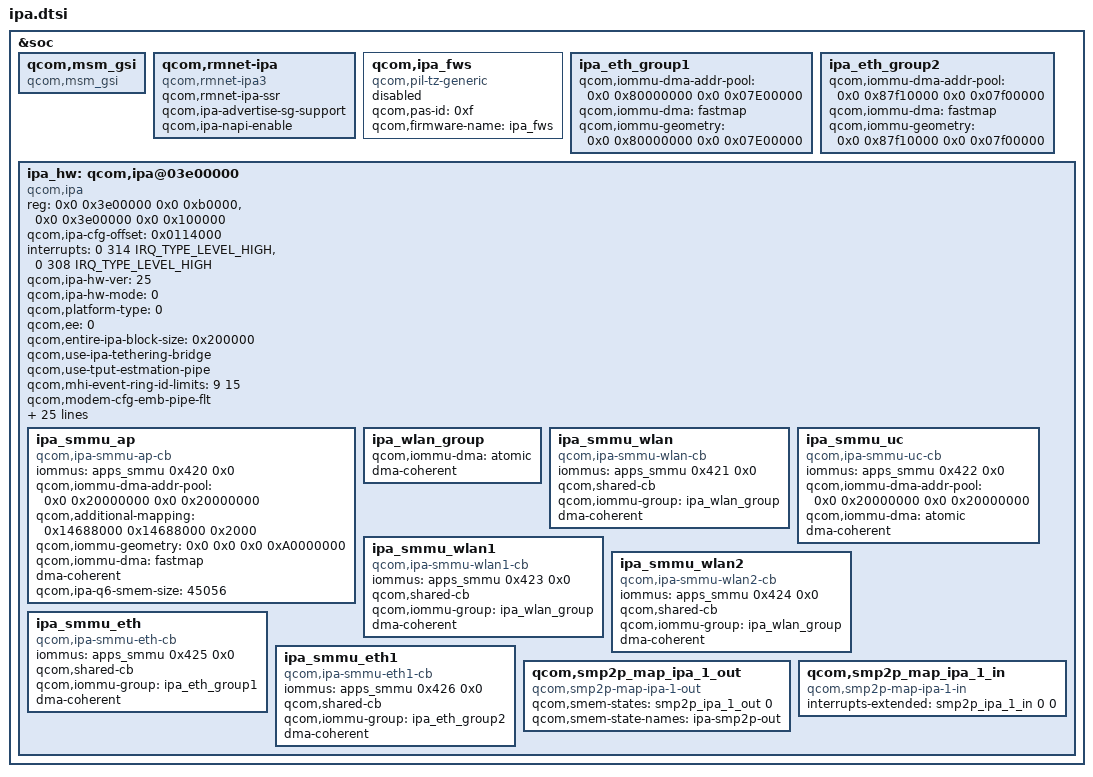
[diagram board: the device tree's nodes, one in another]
// SPDX-License-Identifier: BSD-3-Clause
/*
 * Copyright (c) 2024 Qualcomm Innovation Center, Inc. All rights reserved.
 */

&soc {
	qcom,msm_gsi {
		compatible = "qcom,msm_gsi";
	};

	qcom,rmnet-ipa {
		compatible = "qcom,rmnet-ipa3";
		qcom,rmnet-ipa-ssr;
		qcom,ipa-advertise-sg-support;
		qcom,ipa-napi-enable;
	};

	qcom,ipa_fws {
		compatible = "qcom,pil-tz-generic";
		qcom,pas-id = <0xf>;
		qcom,firmware-name = "ipa_fws";
		status = "disabled";
	};

	ipa_eth_group1: ipa_eth_group1 {
		qcom,iommu-dma-addr-pool = <0x0 0x80000000 0x0 0x07E00000>;
		qcom,iommu-dma = "fastmap";
		qcom,iommu-geometry = <0x0 0x80000000 0x0 0x07E00000>;
	};

	ipa_eth_group2: ipa_eth_group2 {
		qcom,iommu-dma-addr-pool = <0x0 0x87f10000 0x0 0x07f00000>;
		qcom,iommu-dma = "fastmap";
		qcom,iommu-geometry = <0x0 0x87f10000 0x0 0x07f00000>;
	};

	ipa_hw: qcom,ipa@03e00000 {
		compatible = "qcom,ipa";
		reg =
			<0x0 0x3e00000 0x0 0xb0000>,
			<0x0 0x3e00000 0x0 0x100000>;
		reg-names = "ipa-base", "gsi-base";
		qcom,ipa-cfg-offset = <0x0114000>;
		interrupts =
			<0 314 IRQ_TYPE_LEVEL_HIGH>,
			<0 308 IRQ_TYPE_LEVEL_HIGH>;
		interrupt-names = "ipa-irq", "gsi-irq";
		qcom,ipa-hw-ver = <25>; /* IPA core version = IPAv6.0 */
		qcom,ipa-hw-mode = <0>; // IPA_HW_MODE_NORMAL
		qcom,platform-type = <0>; /* MDM platform */
		qcom,ee = <0>;
		qcom,entire-ipa-block-size = <0x200000>;
		qcom,use-ipa-tethering-bridge;
		qcom,use-tput-estmation-pipe;
		qcom,mhi-event-ring-id-limits = <9 15>;
		qcom,modem-cfg-emb-pipe-flt;
		qcom,use-xbl-boot;
		qcom,arm-smmu;
		qcom,smmu-fast-map;
		qcom,use-64-bit-dma-mask;
		qcom,ipa-wdi3-over-gsi;
		qcom,ipa-wdi3-holb-2g = <15>;
		qcom,ipa-wdi3-holb-5g = <31>;
		qcom,ipa-endp-delay-wa-v2;
		qcom,tx-wrapper-cache-max-size = <400>;
		qcom,ipa-gpi-event-rp-ddr;
		qcom,ulso-ip-id-min-linux-val = <0>;
		qcom,ulso-ip-id-max-linux-val = <0xffff>;
		qcom,ulso-ip-id-min-windows-val = <0>;
		qcom,ulso-ip-id-max-windows-val = <0x7fff>;
		qcom,wan-use-skb-page;

		clock-names = "core_clk";
		clocks = <&rpmhcc RPMH_IPA_CLK>;
		qcom,interconnect,num-cases = <5>;
		qcom,interconnect,num-paths = <3>;
		qcom,max_num_smmu_cb = <7>;
		qcom,filter-start-id = <768>;
		qcom,ipa-iemac;
		qcom,lan-rx-napi;
		qcom,tx-napi;
		qcom,tx-poll;
		qcom,lan-coal-enable;

		ipa_smmu_ap: ipa_smmu_ap {
			compatible = "qcom,ipa-smmu-ap-cb";
			iommus = <&apps_smmu 0x420 0x0>;
			qcom,iommu-dma-addr-pool = <0x0 0x20000000 0x0 0x20000000>;
			qcom,additional-mapping =
				/* modem tables in IMEM */
				<0x14688000 0x14688000 0x2000>;
			qcom,iommu-geometry = <0x0 0x0 0x0 0xA0000000>;
			qcom,iommu-dma = "fastmap";
			dma-coherent;
			qcom,ipa-q6-smem-size = <45056>;
		};

		ipa_wlan_group: ipa_wlan_group {
			qcom,iommu-dma = "atomic";
			dma-coherent;
		};

		ipa_smmu_wlan: ipa_smmu_wlan {
			compatible = "qcom,ipa-smmu-wlan-cb";
			iommus = <&apps_smmu 0x421 0x0>;
			qcom,shared-cb;
			qcom,iommu-group = <&ipa_wlan_group>;
			dma-coherent;
		};

		ipa_smmu_uc: ipa_smmu_uc {
			compatible = "qcom,ipa-smmu-uc-cb";
			iommus = <&apps_smmu 0x422 0x0>;
			qcom,iommu-dma-addr-pool = <0x0 0x20000000 0x0 0x20000000>;
			qcom,iommu-dma = "atomic";
			dma-coherent;
		};

		ipa_smmu_wlan1: ipa_smmu_wlan1 {
			compatible = "qcom,ipa-smmu-wlan1-cb";
			iommus = <&apps_smmu 0x423 0x0>;
			qcom,shared-cb;
			qcom,iommu-group = <&ipa_wlan_group>;
			dma-coherent;
		};

		ipa_smmu_wlan2: ipa_smmu_wlan2 {
			compatible = "qcom,ipa-smmu-wlan2-cb";
			iommus = <&apps_smmu 0x424 0x0>;
			qcom,shared-cb;
			qcom,iommu-group = <&ipa_wlan_group>;
			dma-coherent;
		};

		ipa_smmu_eth: ipa_smmu_eth {
			compatible = "qcom,ipa-smmu-eth-cb";
			iommus = <&apps_smmu 0x425 0x0>;
			qcom,shared-cb;
			qcom,iommu-group = <&ipa_eth_group1>;
			dma-coherent;
		};

		ipa_smmu_eth1: ipa_smmu_eth1 {
			compatible = "qcom,ipa-smmu-eth1-cb";
			iommus = <&apps_smmu 0x426 0x0>;
			qcom,shared-cb;
			qcom,iommu-group = <&ipa_eth_group2>;
			dma-coherent;
		};

		/* smp2p information */
		qcom,smp2p_map_ipa_1_out {
			compatible = "qcom,smp2p-map-ipa-1-out";
			qcom,smem-states = <&smp2p_ipa_1_out 0>;
			qcom,smem-state-names = "ipa-smp2p-out";
		};

		qcom,smp2p_map_ipa_1_in {
			compatible = "qcom,smp2p-map-ipa-1-in";
			interrupts-extended = <&smp2p_ipa_1_in 0 0>;
			interrupt-names = "ipa-smp2p-in";
		};
	};

};
